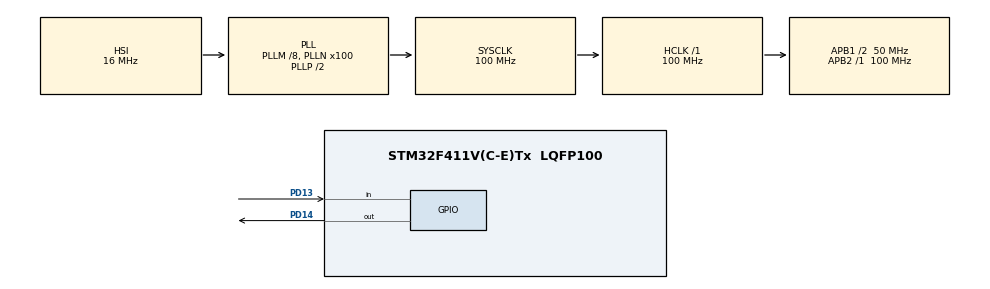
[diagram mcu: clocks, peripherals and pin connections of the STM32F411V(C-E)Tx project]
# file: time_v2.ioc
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Mcu.Family=STM32F4
Mcu.Name=STM32F411V(C-E)Tx
Mcu.Package=LQFP100
NVIC.PriorityGroup=NVIC_PRIORITYGROUP_4
PD13.Signal=GPIO_Input
PD14.GPIO_ModeDefaultOutputPP=GPIO_MODE_OUTPUT_PP
PD14.Signal=GPIO_Output
ProjectManager.HeapSize=0x200
ProjectManager.StackSize=0x400
ProjectManager.TargetToolchain=SW4STM32
RCC.48MHZClocksFreq_Value=50000000
RCC.AHBFreq_Value=100000000
RCC.APB1CLKDivider=RCC_HCLK_DIV2
RCC.APB1Freq_Value=50000000
RCC.APB1TimFreq_Value=100000000
RCC.APB2Freq_Value=100000000
RCC.APB2TimFreq_Value=100000000
RCC.CortexFreq_Value=100000000
RCC.HCLKFreq_Value=100000000
RCC.HSE_VALUE=25000000
RCC.HSI_VALUE=16000000
RCC.LSE_VALUE=32768
RCC.PLLM=8
RCC.PLLN=100
RCC.SYSCLKFreq_VALUE=100000000
RCC.SYSCLKSource=RCC_SYSCLKSOURCE_PLLCLK
RCC.VCOOutputFreq_Value=200000000
TIM2.Period=999999
TIM2.Prescaler=99
VP_TIM2_VS_ClockSourceINT.Mode=Internal
board=time_v2

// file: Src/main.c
/**
  ******************************************************************************
  * File Name          : main.c
  * Description        : Main program body
  ******************************************************************************
  *
  * COPYRIGHT(c) 2016 STMicroelectronics
  *
  * Redistribution and use in source and binary forms, with or without modification,
  * are permitted provided that the following conditions are met:
  *   1. Redistributions of source code must retain the above copyright notice,
  *      this list of conditions and the following disclaimer.
  *   2. Redistributions in binary form must reproduce the above copyright notice,
  *      this list of conditions and the following disclaimer in the documentation
  *      and/or other materials provided with the distribution.
  *   3. Neither the name of STMicroelectronics nor the names of its contributors
  *      may be used to endorse or promote products derived from this software
  *      without specific prior written permission.
  *
  * THIS SOFTWARE IS PROVIDED BY THE COPYRIGHT HOLDERS AND CONTRIBUTORS "AS IS"
  * AND ANY EXPRESS OR IMPLIED WARRANTIES, INCLUDING, BUT NOT LIMITED TO, THE
  * IMPLIED WARRANTIES OF MERCHANTABILITY AND FITNESS FOR A PARTICULAR PURPOSE ARE
  * DISCLAIMED. IN NO EVENT SHALL THE COPYRIGHT HOLDER OR CONTRIBUTORS BE LIABLE
  * FOR ANY DIRECT, INDIRECT, INCIDENTAL, SPECIAL, EXEMPLARY, OR CONSEQUENTIAL
  * DAMAGES (INCLUDING, BUT NOT LIMITED TO, PROCUREMENT OF SUBSTITUTE GOODS OR
  * SERVICES; LOSS OF USE, DATA, OR PROFITS; OR BUSINESS INTERRUPTION) HOWEVER
  * CAUSED AND ON ANY THEORY OF LIABILITY, WHETHER IN CONTRACT, STRICT LIABILITY,
  * OR TORT (INCLUDING NEGLIGENCE OR OTHERWISE) ARISING IN ANY WAY OUT OF THE USE
  * OF THIS SOFTWARE, EVEN IF ADVISED OF THE POSSIBILITY OF SUCH DAMAGE.
  *
  ******************************************************************************
  */
#include "main.h"
#include "stm32f4xx_hal.h"
#include "tim.h"
#include "gpio.h"

/* USER CODE BEGIN PV */
/* Private variables ---------------------------------------------------------*/

/* USER CODE END PV */

void SystemClock_Config(void);
void Error_Handler(void);

/* USER CODE BEGIN PFP */
/* Private function prototypes -----------------------------------------------*/
void blink(uint32_t blink_time) {
	if(TIM2->CNT==blink_time){
		HAL_GPIO_WritePin(GPIOD,GPIO_PIN_14, GPIO_PIN_SET);
	}
	if(TIM2->CNT==2*blink_time-1) {
		HAL_GPIO_WritePin(GPIOD,GPIO_PIN_14, GPIO_PIN_RESET);
	}
}

void sonic_talk(GPIO_TypeDef* TRIG_GPIOx, uint16_t TRIG_GPIO_Pin, GPIO_TypeDef* ECHO_GPIOx, uint16_t ECHO_GPIO_Pin, uint16_t max_time_ms){
	//timer t2 with 1MHz clock
	uint32_t start=0;
	uint32_t time, stop=0;
	uint8_t isok=0;
	uint32_t max_time=max_time_ms*1000;
	float dist=0;

	HAL_GPIO_WritePin(TRIG_GPIOx, TRIG_GPIO_Pin, GPIO_PIN_SET);
	TIM2->CNT=0;
	while(TIM2->CNT<=20){
	}
	HAL_GPIO_WritePin(TRIG_GPIOx, TRIG_GPIO_Pin, GPIO_PIN_RESET);

	while(20+max_time-TIM2->CNT>0){

		if(start!=0 && HAL_GPIO_ReadPin(ECHO_GPIOx,ECHO_GPIO_Pin)==GPIO_PIN_RESET){
			stop=TIM2->CNT;
			time=stop-start;
			isok=1;
			break;
		}
		if(start==0 && HAL_GPIO_ReadPin(ECHO_GPIOx,ECHO_GPIO_Pin)==GPIO_PIN_SET){
			start=TIM2->CNT;
		}
	}

	if(isok==1) {
		dist=0.017*time;//cm
	}

}
/* USER CODE END PFP */

int main(void)
{

  /* MCU Configuration----------------------------------------------------------*/

  /* Reset of all peripherals, Initializes the Flash interface and the Systick. */
  HAL_Init();

  /* Configure the system clock */
  SystemClock_Config();

  /* Initialize all configured peripherals */
  MX_GPIO_Init();
  MX_TIM2_Init();

  /* USER CODE BEGIN 2 */
  HAL_TIM_Base_Start(&htim2);
  //TIM2->CNT=0; //for blink method

  /* USER CODE END 2 */

  /* Infinite loop */
  while (1)
  {

  /* USER CODE BEGIN 3 */
	 // blink(400000);
	  sonic_talk(GPIOD, GPIO_PIN_14, GPIOD, GPIO_PIN_13,100);
  }
  /* USER CODE END 3 */

}

/** System Clock Configuration
*/
void SystemClock_Config(void)
{

  RCC_OscInitTypeDef RCC_OscInitStruct;
  RCC_ClkInitTypeDef RCC_ClkInitStruct;

    /**Configure the main internal regulator output voltage
    */
  __HAL_RCC_PWR_CLK_ENABLE();

  __HAL_PWR_VOLTAGESCALING_CONFIG(PWR_REGULATOR_VOLTAGE_SCALE1);

    /**Initializes the CPU, AHB and APB busses clocks
    */
  RCC_OscInitStruct.OscillatorType = RCC_OSCILLATORTYPE_HSI;
  RCC_OscInitStruct.HSIState = RCC_HSI_ON;
  RCC_OscInitStruct.HSICalibrationValue = 16;
  RCC_OscInitStruct.PLL.PLLState = RCC_PLL_ON;
  RCC_OscInitStruct.PLL.PLLSource = RCC_PLLSOURCE_HSI;
  RCC_OscInitStruct.PLL.PLLM = 8;
  RCC_OscInitStruct.PLL.PLLN = 100;
  RCC_OscInitStruct.PLL.PLLP = RCC_PLLP_DIV2;
  RCC_OscInitStruct.PLL.PLLQ = 4;
  if (HAL_RCC_OscConfig(&RCC_OscInitStruct) != HAL_OK)
  {
    Error_Handler();
  }

    /**Initializes the CPU, AHB and APB busses clocks
    */
  RCC_ClkInitStruct.ClockType = RCC_CLOCKTYPE_HCLK|RCC_CLOCKTYPE_SYSCLK
                              |RCC_CLOCKTYPE_PCLK1|RCC_CLOCKTYPE_PCLK2;
  RCC_ClkInitStruct.SYSCLKSource = RCC_SYSCLKSOURCE_PLLCLK;
  RCC_ClkInitStruct.AHBCLKDivider = RCC_SYSCLK_DIV1;
  RCC_ClkInitStruct.APB1CLKDivider = RCC_HCLK_DIV2;
  RCC_ClkInitStruct.APB2CLKDivider = RCC_HCLK_DIV1;

  if (HAL_RCC_ClockConfig(&RCC_ClkInitStruct, FLASH_LATENCY_3) != HAL_OK)
  {
    Error_Handler();
  }

    /**Configure the Systick interrupt time
    */
  HAL_SYSTICK_Config(HAL_RCC_GetHCLKFreq()/1000);

    /**Configure the Systick
    */
  HAL_SYSTICK_CLKSourceConfig(SYSTICK_CLKSOURCE_HCLK);

  /* SysTick_IRQn interrupt configuration */
  HAL_NVIC_SetPriority(SysTick_IRQn, 0, 0);
}

void Error_Handler(void)
{
  while(1)
  {
  }
}

/************************ (C) COPYRIGHT STMicroelectronics *****END OF FILE****/
